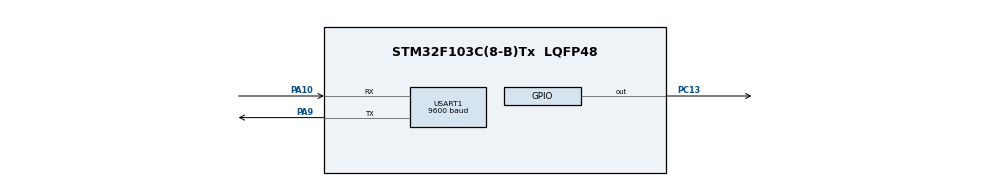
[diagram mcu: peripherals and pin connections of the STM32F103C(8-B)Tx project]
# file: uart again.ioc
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Mcu.Family=STM32F1
Mcu.Name=STM32F103C(8-B)Tx
Mcu.Package=LQFP48
NVIC.PriorityGroup=NVIC_PRIORITYGROUP_4
NVIC.USART1_IRQn=true\:0\:0\:false\:false\:true\:true\:true\:true
PA10.Mode=Asynchronous
PA10.Signal=USART1_RX
PA13.Mode=Serial_Wire
PA13.Signal=SYS_JTMS-SWDIO
PA14.Mode=Serial_Wire
PA14.Signal=SYS_JTCK-SWCLK
PA9.Mode=Asynchronous
PA9.Signal=USART1_TX
PC13-TAMPER-RTC.Signal=GPIO_Output
ProjectManager.HeapSize=0x200
ProjectManager.StackSize=0x400
ProjectManager.TargetToolchain=STM32CubeIDE
RCC.APB1Freq_Value=8000000
RCC.APB2Freq_Value=8000000
TIM2.Period=1000-1
TIM2.Prescaler=720-1
USART1.BaudRate=9600
USART1.VirtualMode=VM_ASYNC
VP_TIM2_VS_ClockSourceITR.Mode=TriggerSource_ITR0
board=custom

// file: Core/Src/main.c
/* USER CODE BEGIN Header */
/**
  ******************************************************************************
  * @file           : main.c
  * @brief          : Main program body
  ******************************************************************************
  * @attention
  *
  * Copyright (c) 2025 STMicroelectronics.
  * All rights reserved.
  *
  * This software is licensed under terms that can be found in the LICENSE file
  * in the root directory of this software component.
  * If no LICENSE file comes with this software, it is provided AS-IS.
  *
  ******************************************************************************
  */
/* USER CODE END Header */
#include "main.h"

TIM_HandleTypeDef htim2;

UART_HandleTypeDef huart1;

/* USER CODE BEGIN PV */
uint8_t rx_byte[1];
uint8_t buffer[256];
uint8_t message[]="hi bro!\n\r";
/* USER CODE END PV */

void SystemClock_Config(void);
static void MX_GPIO_Init(void);
static void MX_TIM2_Init(void);
static void MX_USART1_UART_Init(void);

int main(void)
{

  /* MCU Configuration--------------------------------------------------------*/

  /* Reset of all peripherals, Initializes the Flash interface and the Systick. */
  HAL_Init();

  /* Configure the system clock */
  SystemClock_Config();

  /* Initialize all configured peripherals */
  MX_GPIO_Init();
  MX_TIM2_Init();
  MX_USART1_UART_Init();
  /* USER CODE BEGIN 2 */
  HAL_TIM_Base_Start_IT(&htim2);
  HAL_UART_Receive_IT(&huart1, rx_byte, 1);
  /* USER CODE END 2 */

  /* Infinite loop */
  while (1)
  {

  }
}

void SystemClock_Config(void)
{
  RCC_OscInitTypeDef RCC_OscInitStruct = {0};
  RCC_ClkInitTypeDef RCC_ClkInitStruct = {0};

  /** Initializes the RCC Oscillators according to the specified parameters
  * in the RCC_OscInitTypeDef structure.
  */
  RCC_OscInitStruct.OscillatorType = RCC_OSCILLATORTYPE_HSI;
  RCC_OscInitStruct.HSIState = RCC_HSI_ON;
  RCC_OscInitStruct.HSICalibrationValue = RCC_HSICALIBRATION_DEFAULT;
  RCC_OscInitStruct.PLL.PLLState = RCC_PLL_NONE;
  if (HAL_RCC_OscConfig(&RCC_OscInitStruct) != HAL_OK)
  {
    Error_Handler();
  }

  /** Initializes the CPU, AHB and APB buses clocks
  */
  RCC_ClkInitStruct.ClockType = RCC_CLOCKTYPE_HCLK|RCC_CLOCKTYPE_SYSCLK
                              |RCC_CLOCKTYPE_PCLK1|RCC_CLOCKTYPE_PCLK2;
  RCC_ClkInitStruct.SYSCLKSource = RCC_SYSCLKSOURCE_HSI;
  RCC_ClkInitStruct.AHBCLKDivider = RCC_SYSCLK_DIV1;
  RCC_ClkInitStruct.APB1CLKDivider = RCC_HCLK_DIV1;
  RCC_ClkInitStruct.APB2CLKDivider = RCC_HCLK_DIV1;

  if (HAL_RCC_ClockConfig(&RCC_ClkInitStruct, FLASH_LATENCY_0) != HAL_OK)
  {
    Error_Handler();
  }
}

static void MX_TIM2_Init(void)
{

  TIM_SlaveConfigTypeDef sSlaveConfig = {0};
  TIM_MasterConfigTypeDef sMasterConfig = {0};

  htim2.Instance = TIM2;
  htim2.Init.Prescaler = 720-1;
  htim2.Init.CounterMode = TIM_COUNTERMODE_UP;
  htim2.Init.Period = 1000-1;
  htim2.Init.ClockDivision = TIM_CLOCKDIVISION_DIV1;
  htim2.Init.AutoReloadPreload = TIM_AUTORELOAD_PRELOAD_DISABLE;
  if (HAL_TIM_Base_Init(&htim2) != HAL_OK)
  {
    Error_Handler();
  }
  sSlaveConfig.SlaveMode = TIM_SLAVEMODE_DISABLE;
  sSlaveConfig.InputTrigger = TIM_TS_ITR0;
  if (HAL_TIM_SlaveConfigSynchro(&htim2, &sSlaveConfig) != HAL_OK)
  {
    Error_Handler();
  }
  sMasterConfig.MasterOutputTrigger = TIM_TRGO_RESET;
  sMasterConfig.MasterSlaveMode = TIM_MASTERSLAVEMODE_DISABLE;
  if (HAL_TIMEx_MasterConfigSynchronization(&htim2, &sMasterConfig) != HAL_OK)
  {
    Error_Handler();
  }

}

static void MX_USART1_UART_Init(void)
{

  huart1.Instance = USART1;
  huart1.Init.BaudRate = 9600;
  huart1.Init.WordLength = UART_WORDLENGTH_8B;
  huart1.Init.StopBits = UART_STOPBITS_1;
  huart1.Init.Parity = UART_PARITY_NONE;
  huart1.Init.Mode = UART_MODE_TX_RX;
  huart1.Init.HwFlowCtl = UART_HWCONTROL_NONE;
  huart1.Init.OverSampling = UART_OVERSAMPLING_16;
  if (HAL_UART_Init(&huart1) != HAL_OK)
  {
    Error_Handler();
  }

}

static void MX_GPIO_Init(void)
{
  GPIO_InitTypeDef GPIO_InitStruct = {0};

  /* GPIO Ports Clock Enable */
  __HAL_RCC_GPIOC_CLK_ENABLE();
  __HAL_RCC_GPIOA_CLK_ENABLE();

  /*Configure GPIO pin Output Level */
  HAL_GPIO_WritePin(GPIOC, GPIO_PIN_13, GPIO_PIN_RESET);

  /*Configure GPIO pin : PC13 */
  GPIO_InitStruct.Pin = GPIO_PIN_13;
  GPIO_InitStruct.Mode = GPIO_MODE_OUTPUT_PP;
  GPIO_InitStruct.Pull = GPIO_NOPULL;
  GPIO_InitStruct.Speed = GPIO_SPEED_FREQ_LOW;
  HAL_GPIO_Init(GPIOC, &GPIO_InitStruct);

}

/* USER CODE BEGIN 4 */
int i = 0;

uint8_t model[64];
uint8_t year[64];
uint8_t vin[64];
uint8_t speed[64];

//                         key
uint8_t model[64] = {0};//| + |
uint8_t year[64] = {0};// | - |
uint8_t vin[64] = {0};//  | @ |
uint8_t speed[64] = {0};//| $ |
//end of message key:     | ^ |
int mode = 5; // 1-model, 2-year, 3-vin, 4-speed, 5-nothing

void car() {
    int model_pos = 0, year_pos = 0, vin_pos = 0, speed_pos = 0;

    for(int a = 0; a < sizeof(buffer); a++) {
        // Проверка на разделители
        if(buffer[a] == '+') {
            mode = 1;
            continue;
        } else if(buffer[a] == '-') {
            mode = 2;
            continue;
        } else if(buffer[a] == '@') {
            mode = 3;
            continue;
        } else if(buffer[a] == '$') {
            mode = 4;
            continue;
        }

        // Запись в соответствующий массив
        switch(mode) {
            case 1:
                if(model_pos < sizeof(model)-1)
                    model[model_pos++] = buffer[a];
                break;
            case 2:
                if(year_pos < sizeof(year)-1)
                    year[year_pos++] = buffer[a];
                break;
            case 3:
                if(vin_pos < sizeof(vin)-1)
                    vin[vin_pos++] = buffer[a];
                break;
            case 4:
                if(speed_pos < sizeof(speed)-1)
                    speed[speed_pos++] = buffer[a];
                break;
        }
    }

    // Добавляем нулевые терминаторы
    model[model_pos] = '\0';
    year[year_pos] = '\0';
    vin[vin_pos] = '\0';
    speed[speed_pos] = '\0';
    mode = 5;
}
void sendback(){
	i = 0;
    memset(model, 0, sizeof(model));
    memset(year, 0, sizeof(year));
    memset(vin, 0, sizeof(vin));
    memset(speed, 0, sizeof(speed));
	char output_buffer[512];
	car();
	//сбор данных в char output_buffer
    snprintf(output_buffer, sizeof(output_buffer),
        "model: %s\r\n"
        "speed: %s\r\n"
        "year: %s\r\n"
        "vin: %s\r\n",
        model, speed, year, vin);
   // int len = strlen(output_buffer)
	HAL_UART_Transmit_IT(&huart1, (uint8_t*)output_buffer, strlen(output_buffer));
}

/*void function() {
    buffer[i] = '\0';  // Завершаем строку
    i = 0;

    size_t size = strlen((char*)buffer);
    uint8_t percent = (uint8_t)(((float)size / 255.0f) * 100.0f + 0.5f);

    // Буфер для итогового сообщения
    char output_buffer[255];

    // Формируем строку
    int len = snprintf(
        output_buffer,
        sizeof(output_buffer),
        "buffer is %u%% full\r\ncontent: %s\r\n",
        percent,
        buffer
    );

    // Отправляем всё одной командой
    HAL_UART_Transmit_IT(&huart1, (uint8_t*)output_buffer, len);

    // Очищаем содержимое
    memset(buffer, 0, sizeof(buffer));
}*/

void HAL_UART_RxCpltCallback(UART_HandleTypeDef *huart) {
    if (huart->Instance == USART1) {

    	if(rx_byte[0]=='^'){
    		sendback();
    	}else{buffer[i]=rx_byte[0];
    	i+=1;}
        HAL_UART_Receive_IT(&huart1, rx_byte, 1);
    }
}
void HAL_TIM_PeriodElapsedCallback(TIM_HandleTypeDef *htim)
{
        if(htim->Instance == TIM2) //check if the interrupt comes from TIM2
        {
        	uint8_t hi="enter vin, year, model and speed of car\r\nkeys:\r\n+model+\r\n-year-\r\n@vin@\r\n$speed$\r\nuse ^ to and message";
        	        HAL_UART_Transmit_IT(&huart1, hi, sizeof(hi)); // Отправляем данные через USART1
        	        HAL_TIM_Base_Stop_IT(&htim2);
        	        GPIOC -> ODR ^= (1<<13);
        }
}
/* USER CODE END 4 */

void Error_Handler(void)
{
  __disable_irq();
  while (1)
  {
  }
}
